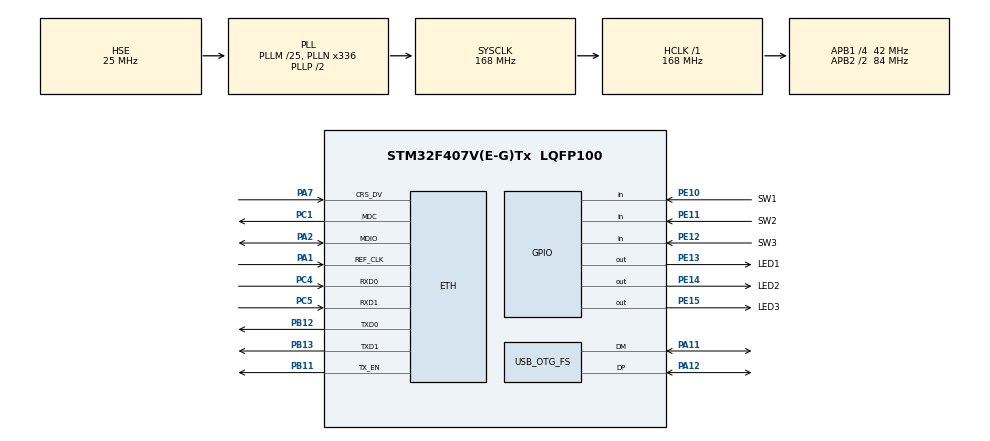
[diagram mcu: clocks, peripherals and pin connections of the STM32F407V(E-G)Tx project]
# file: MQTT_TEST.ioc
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ETH.MediaInterface=HAL_ETH_RMII_MODE
FREERTOS.Tasks01=Task01,24,512,StartTask01,As weak,NULL,Dynamic,NULL,NULL;myTask02,8,256,StartTask02,As weak,NULL,Dynamic,NULL,NULL;myTask03,8,256,StartTask03,As weak,NULL,Dynamic,NULL,NULL
FREERTOS.configCHECK_FOR_STACK_OVERFLOW=2
FREERTOS.configENABLE_FPU=1
FREERTOS.configMINIMAL_STACK_SIZE=256
FREERTOS.configTOTAL_HEAP_SIZE=20480
FREERTOS.configUSE_MALLOC_FAILED_HOOK=1
FREERTOS.configUSE_NEWLIB_REENTRANT=1
LWIP.BSP.number=1
LWIP.DEFAULT_THREAD_STACKSIZE=2048
LWIP.GATEWAY_ADDRESS=192.168.000.001
LWIP.IP_ADDRESS=192.168.000.002
LWIP.LWIP_DHCP=0
LWIP.MEM_SIZE=2048
LWIP.NETMASK_ADDRESS=255.255.255.000
LWIP.PBUF_POOL_BUFSIZE=1024
LWIP.TCPIP_THREAD_STACKSIZE=2048
LWIP.Version=v2.1.2_Cube
LWIP0.BSP.STBoard=false
LWIP0.BSP.api=BSP_COMPONENT_DRIVER
LWIP0.BSP.component=DP83848
LWIP0.BSP.instance=DP83848
LWIP0.BSP.name=Driver_PHY
LWIP0.BSP.semaphore=S_DP83848
LWIP0.BSP.solution=DP83848
Mcu.Family=STM32F4
Mcu.Name=STM32F407V(E-G)Tx
Mcu.Package=LQFP100
NVIC.ETH_IRQn=true\:5\:0\:false\:false\:true\:true\:false\:true\:true
NVIC.OTG_FS_IRQn=true\:5\:0\:false\:false\:true\:true\:false\:true\:true
NVIC.PriorityGroup=NVIC_PRIORITYGROUP_4
NVIC.TIM8_TRG_COM_TIM14_IRQn=true\:15\:0\:false\:false\:true\:false\:false\:true\:true
NVIC.TimeBase=TIM8_TRG_COM_TIM14_IRQn
NVIC.TimeBaseIP=TIM14
PA1.Mode=RMII
PA1.Signal=ETH_REF_CLK
PA11.Mode=Device_Only
PA11.Signal=USB_OTG_FS_DM
PA12.Mode=Device_Only
PA12.Signal=USB_OTG_FS_DP
PA13.Mode=Serial_Wire
PA13.Signal=SYS_JTMS-SWDIO
PA14.Mode=Serial_Wire
PA14.Signal=SYS_JTCK-SWCLK
PA2.Mode=RMII
PA2.Signal=ETH_MDIO
PA7.Mode=RMII
PA7.Signal=ETH_CRS_DV
PB11.Mode=RMII
PB11.Signal=ETH_TX_EN
PB12.Mode=RMII
PB12.Signal=ETH_TXD0
PB13.Mode=RMII
PB13.Signal=ETH_TXD1
PC1.Mode=RMII
PC1.Signal=ETH_MDC
PC4.Mode=RMII
PC4.Signal=ETH_RXD0
PC5.Mode=RMII
PC5.Signal=ETH_RXD1
PE10.GPIO_Label=SW1
PE10.Signal=GPIO_Input
PE11.GPIO_Label=SW2
PE11.Signal=GPIO_Input
PE12.GPIO_Label=SW3
PE12.Signal=GPIO_Input
PE13.GPIO_Label=LED1
PE13.Signal=GPIO_Output
PE14.GPIO_Label=LED2
PE14.Signal=GPIO_Output
PE15.GPIO_Label=LED3
PE15.Signal=GPIO_Output
PH0-OSC_IN.Mode=HSE-External-Oscillator
PH0-OSC_IN.Signal=RCC_OSC_IN
PH1-OSC_OUT.Mode=HSE-External-Oscillator
PH1-OSC_OUT.Signal=RCC_OSC_OUT
ProjectManager.HeapSize=0x600
ProjectManager.StackSize=0x600
ProjectManager.TargetToolchain=STM32CubeIDE
RCC.48MHZClocksFreq_Value=48000000
RCC.AHBFreq_Value=168000000
RCC.APB1CLKDivider=RCC_HCLK_DIV4
RCC.APB1Freq_Value=42000000
RCC.APB1TimFreq_Value=84000000
RCC.APB2CLKDivider=RCC_HCLK_DIV2
RCC.APB2Freq_Value=84000000
RCC.APB2TimFreq_Value=168000000
RCC.CortexFreq_Value=168000000
RCC.HCLKFreq_Value=168000000
RCC.HSE_VALUE=25000000
RCC.HSI_VALUE=16000000
RCC.LSE_VALUE=32768
RCC.PLLM=25
RCC.PLLN=336
RCC.PLLQ=7
RCC.SYSCLKFreq_VALUE=168000000
RCC.SYSCLKSource=RCC_SYSCLKSOURCE_PLLCLK
RCC.VCOOutputFreq_Value=336000000
USB_DEVICE.CLASS_NAME_FS=CDC
USB_DEVICE.VirtualMode-CDC_FS=Cdc
USB_DEVICE.VirtualModeFS=Cdc_FS
USB_OTG_FS.VirtualMode=Device_Only
VP_FREERTOS_VS_CMSIS_V2.Mode=CMSIS_V2
VP_LWIP_VS_Enabled.Mode=Enabled
VP_SYS_VS_tim14.Mode=TIM14
VP_USB_DEVICE_VS_USB_DEVICE_CDC_FS.Mode=CDC_FS
board=custom

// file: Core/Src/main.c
/* USER CODE BEGIN Header */
/**
  ******************************************************************************
  * @file           : main.c
  * @brief          : Main program body
  ******************************************************************************
  * @attention
  *
  * Copyright (c) 2026 STMicroelectronics.
  * All rights reserved.
  *
  * This software is licensed under terms that can be found in the LICENSE file
  * in the root directory of this software component.
  * If no LICENSE file comes with this software, it is provided AS-IS.
  *
  ******************************************************************************
  */
/* USER CODE END Header */
#include "main.h"
#include "cmsis_os.h"
#include "lwip.h"
#include "usb_device.h"
#include "gpio.h"

/* USER CODE BEGIN Includes */
#include "usbd_cdc_if.h"
/* USER CODE END Includes */

void SystemClock_Config(void);
void MX_FREERTOS_Init(void);
/* USER CODE BEGIN PFP */
//int _write(int fd, unsigned char *buf, int len) {
//  if (fd == 1 || fd == 2) {
//	  CDC_Transmit_FS(buf, len);
//  }
//  return len;
//}
/* USER CODE END PFP */

int main(void)
{

  /* MCU Configuration--------------------------------------------------------*/

  /* Reset of all peripherals, Initializes the Flash interface and the Systick. */
  HAL_Init();

  /* Configure the system clock */
  SystemClock_Config();

  /* Initialize all configured peripherals */
  MX_GPIO_Init();

  /* Init scheduler */
  osKernelInitialize();  /* Call init function for freertos objects (in cmsis_os2.c) */
  MX_FREERTOS_Init();

  /* Start scheduler */
  osKernelStart();

  /* We should never get here as control is now taken by the scheduler */

  /* Infinite loop */
  while (1)
  {

  }
}

void SystemClock_Config(void)
{
  RCC_OscInitTypeDef RCC_OscInitStruct = {0};
  RCC_ClkInitTypeDef RCC_ClkInitStruct = {0};

  /** Configure the main internal regulator output voltage
  */
  __HAL_RCC_PWR_CLK_ENABLE();
  __HAL_PWR_VOLTAGESCALING_CONFIG(PWR_REGULATOR_VOLTAGE_SCALE1);

  /** Initializes the RCC Oscillators according to the specified parameters
  * in the RCC_OscInitTypeDef structure.
  */
  RCC_OscInitStruct.OscillatorType = RCC_OSCILLATORTYPE_HSE;
  RCC_OscInitStruct.HSEState = RCC_HSE_ON;
  RCC_OscInitStruct.PLL.PLLState = RCC_PLL_ON;
  RCC_OscInitStruct.PLL.PLLSource = RCC_PLLSOURCE_HSE;
  RCC_OscInitStruct.PLL.PLLM = 25;
  RCC_OscInitStruct.PLL.PLLN = 336;
  RCC_OscInitStruct.PLL.PLLP = RCC_PLLP_DIV2;
  RCC_OscInitStruct.PLL.PLLQ = 7;
  if (HAL_RCC_OscConfig(&RCC_OscInitStruct) != HAL_OK)
  {
    Error_Handler();
  }

  /** Initializes the CPU, AHB and APB buses clocks
  */
  RCC_ClkInitStruct.ClockType = RCC_CLOCKTYPE_HCLK|RCC_CLOCKTYPE_SYSCLK
                              |RCC_CLOCKTYPE_PCLK1|RCC_CLOCKTYPE_PCLK2;
  RCC_ClkInitStruct.SYSCLKSource = RCC_SYSCLKSOURCE_PLLCLK;
  RCC_ClkInitStruct.AHBCLKDivider = RCC_SYSCLK_DIV1;
  RCC_ClkInitStruct.APB1CLKDivider = RCC_HCLK_DIV4;
  RCC_ClkInitStruct.APB2CLKDivider = RCC_HCLK_DIV2;

  if (HAL_RCC_ClockConfig(&RCC_ClkInitStruct, FLASH_LATENCY_5) != HAL_OK)
  {
    Error_Handler();
  }
}

void HAL_TIM_PeriodElapsedCallback(TIM_HandleTypeDef *htim)
{
  if (htim->Instance == TIM14)
  {
    HAL_IncTick();
  }
}

void Error_Handler(void)
{
  __disable_irq();
  while (1)
  {
  }
}

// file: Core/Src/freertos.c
/* USER CODE BEGIN Header */
/**
  ******************************************************************************
  * File Name          : freertos.c
  * Description        : Code for freertos applications
  ******************************************************************************
  * @attention
  *
  * Copyright (c) 2026 STMicroelectronics.
  * All rights reserved.
  *
  * This software is licensed under terms that can be found in the LICENSE file
  * in the root directory of this software component.
  * If no LICENSE file comes with this software, it is provided AS-IS.
  *
  ******************************************************************************
  */
/* USER CODE END Header */

#include "FreeRTOS.h"
#include "task.h"
#include "main.h"
#include "cmsis_os.h"

/* Definitions for Task01 */
osThreadId_t Task01Handle;
const osThreadAttr_t Task01_attributes = {
  .name = "Task01",
  .stack_size = 512 * 4,
  .priority = (osPriority_t) osPriorityNormal,
};
/* Definitions for myTask02 */
osThreadId_t myTask02Handle;
const osThreadAttr_t myTask02_attributes = {
  .name = "myTask02",
  .stack_size = 256 * 4,
  .priority = (osPriority_t) osPriorityLow,
};
/* Definitions for myTask03 */
osThreadId_t myTask03Handle;
const osThreadAttr_t myTask03_attributes = {
  .name = "myTask03",
  .stack_size = 256 * 4,
  .priority = (osPriority_t) osPriorityLow,
};

void StartTask01(void *argument);
void StartTask02(void *argument);
void StartTask03(void *argument);

extern void MX_LWIP_Init(void);
extern void MX_USB_DEVICE_Init(void);
void MX_FREERTOS_Init(void); /* (MISRA C 2004 rule 8.1) */

/* Hook prototypes */
void vApplicationStackOverflowHook(xTaskHandle xTask, signed char *pcTaskName);
void vApplicationMallocFailedHook(void);

/* USER CODE BEGIN 4 */
void vApplicationStackOverflowHook(xTaskHandle xTask, signed char *pcTaskName)
{
	HAL_GPIO_WritePin(LED3_GPIO_Port, LED3_Pin, GPIO_PIN_SET);
   /* Run time stack overflow checking is performed if
   configCHECK_FOR_STACK_OVERFLOW is defined to 1 or 2. This hook function is
   called if a stack overflow is detected. */
}
/* USER CODE END 4 */

/* USER CODE BEGIN 5 */
void vApplicationMallocFailedHook(void)
{
	HAL_GPIO_WritePin(LED3_GPIO_Port, LED3_Pin, GPIO_PIN_SET);
   /* vApplicationMallocFailedHook() will only be called if
   configUSE_MALLOC_FAILED_HOOK is set to 1 in FreeRTOSConfig.h. It is a hook
   function that will get called if a call to pvPortMalloc() fails.
   pvPortMalloc() is called internally by the kernel whenever a task, queue,
   timer or semaphore is created. It is also called by various parts of the
   demo application. If heap_1.c or heap_2.c are used, then the size of the
   heap available to pvPortMalloc() is defined by configTOTAL_HEAP_SIZE in
   FreeRTOSConfig.h, and the xPortGetFreeHeapSize() API function can be used
   to query the size of free heap space that remains (although it does not
   provide information on how the remaining heap might be fragmented). */
}
/* USER CODE END 5 */

void MX_FREERTOS_Init(void) {

  /* Create the thread(s) */
  /* creation of Task01 */
  Task01Handle = osThreadNew(StartTask01, NULL, &Task01_attributes);

  /* creation of myTask02 */
  myTask02Handle = osThreadNew(StartTask02, NULL, &myTask02_attributes);

  /* creation of myTask03 */
  myTask03Handle = osThreadNew(StartTask03, NULL, &myTask03_attributes);

}

__weak void StartTask01(void *argument)
{
  /* init code for LWIP */
  MX_LWIP_Init();

  /* init code for USB_DEVICE */
  MX_USB_DEVICE_Init();
  for(;;)
  {
    osDelay(1);
  }
}

__weak void StartTask02(void *argument)
{
  for(;;)
  {
    osDelay(1);
  }
}

__weak void StartTask03(void *argument)
{
  for(;;)
  {
    osDelay(1);
  }
}
